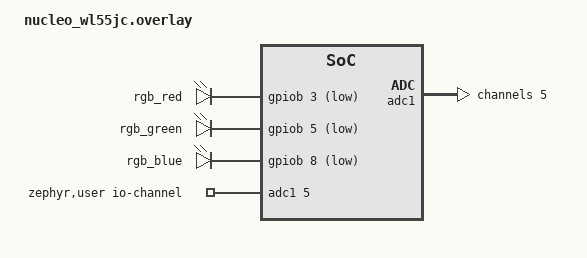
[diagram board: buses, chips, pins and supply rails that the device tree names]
#include <zephyr/dt-bindings/gpio/gpio.h>
#include <zephyr/dt-bindings/adc/adc.h>

/ {
	aliases {
		led0 = &blue_led_1;       /* kept from blink_basic */
		rgb-red   = &rgb_red;
		rgb-green = &rgb_green;
		rgb-blue  = &rgb_blue;
	};

	/* External RGB LED, COMMON ANODE (COM -> 3V3), so ACTIVE_LOW:
	 * pin = 0 -> LED on, pin = 1 -> LED off.
	 * Arduino header: D3 = PB3, D4 = PB5, D5 = PB8. */
	rgb_leds {
		compatible = "gpio-leds";
		rgb_red: rgb_red {
			gpios = <&gpiob 3 GPIO_ACTIVE_LOW>;
		};
		rgb_green: rgb_green {
			gpios = <&gpiob 5 GPIO_ACTIVE_LOW>;
		};
		rgb_blue: rgb_blue {
			gpios = <&gpiob 8 GPIO_ACTIVE_LOW>;
		};
	};
};

/* Light sensor (LDR module) on A0 = PB1 = ADC1 channel 5.
 * The pin muxing (pinctrl) is already done by the board Devicetree. */
/ {
	zephyr,user {
		io-channels = <&adc1 5>;
	};
};

&adc1 {
	#address-cells = <1>;
	#size-cells = <0>;

	channel@5 {
		reg = <5>;
		zephyr,gain = "ADC_GAIN_1";
		zephyr,reference = "ADC_REF_INTERNAL";
		zephyr,acquisition-time = <ADC_ACQ_TIME_DEFAULT>;
		zephyr,resolution = <12>;
	};
};
